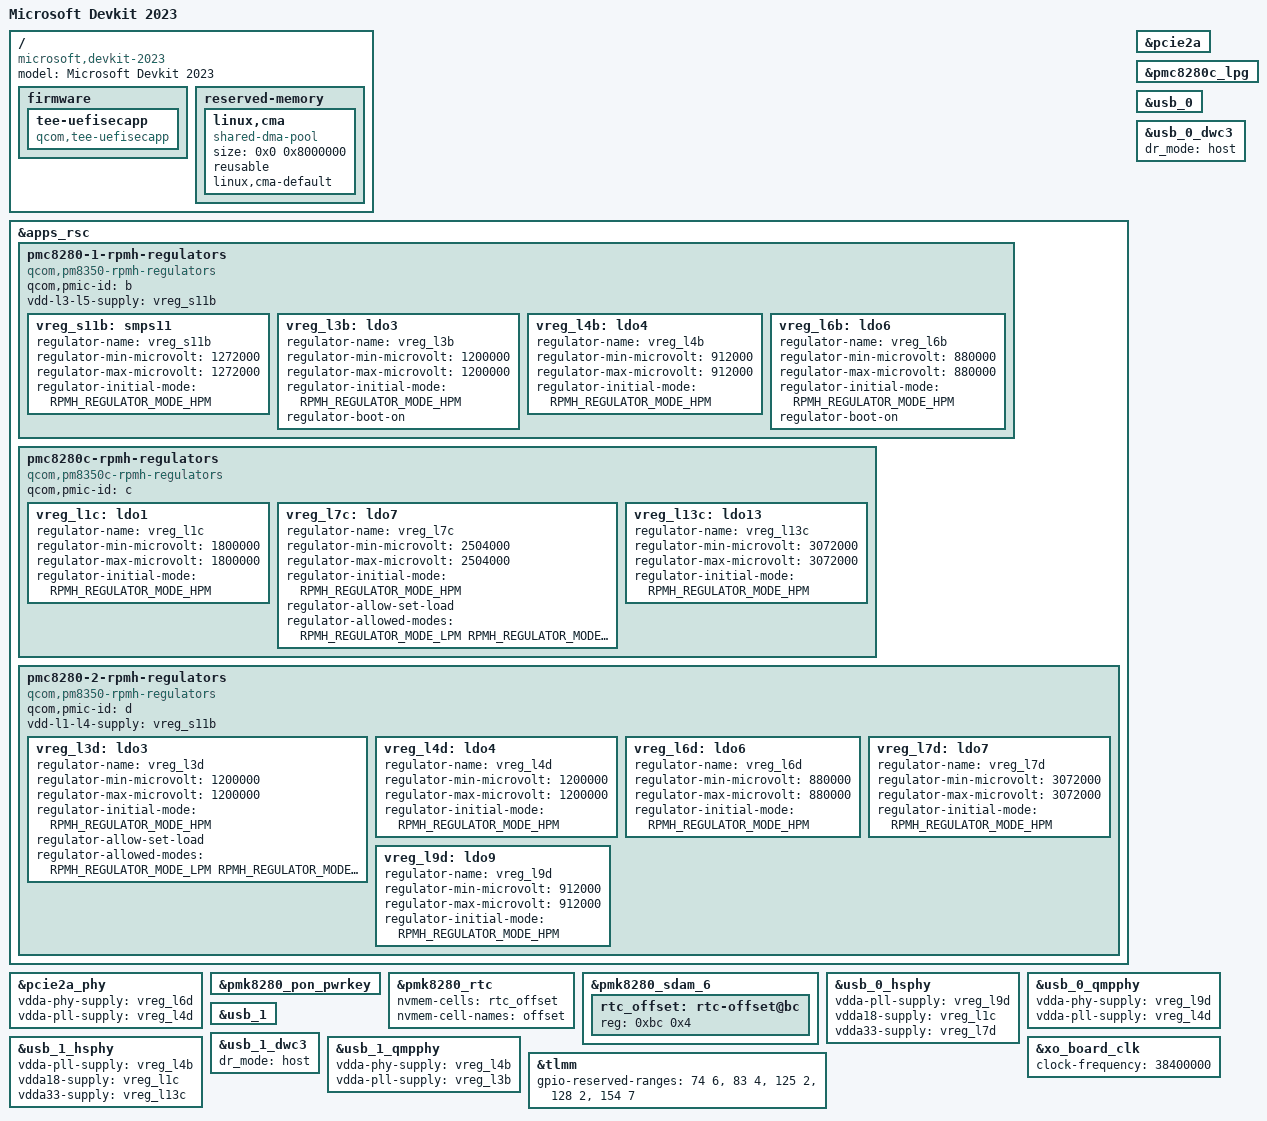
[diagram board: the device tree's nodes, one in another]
// SPDX-License-Identifier: BSD-3-Clause
/*
 * Copyright (c) 2021, The Linux Foundation. All rights reserved.
 * Copyright (c) 2023, Linaro Limited
 */

/dts-v1/;

#include <dt-bindings/gpio/gpio.h>
#include <dt-bindings/regulator/qcom,rpmh-regulator.h>

#include "sc8280xp.dtsi"
#include "sc8280xp-pmics.dtsi"

/ {
	model = "Microsoft Devkit 2023";
	compatible = "microsoft,devkit-2023", "qcom,sc8280xp";

	firmware {
		tee-uefisecapp {
			compatible = "qcom,tee-uefisecapp";
		};
	};

	reserved-memory {
		linux,cma {
			compatible = "shared-dma-pool";
			size = <0x0 0x8000000>;
			reusable;
			linux,cma-default;
		};
	};
};

&apps_rsc {
	pmc8280-1-rpmh-regulators {
		compatible = "qcom,pm8350-rpmh-regulators";
		qcom,pmic-id = "b";

		vdd-l3-l5-supply = <&vreg_s11b>;

		vreg_s11b: smps11 {
			regulator-name = "vreg_s11b";
			regulator-min-microvolt = <1272000>;
			regulator-max-microvolt = <1272000>;
			regulator-initial-mode = <RPMH_REGULATOR_MODE_HPM>;
		};

		vreg_l3b: ldo3 {
			regulator-name = "vreg_l3b";
			regulator-min-microvolt = <1200000>;
			regulator-max-microvolt = <1200000>;
			regulator-initial-mode = <RPMH_REGULATOR_MODE_HPM>;
			regulator-boot-on;
		};

		vreg_l4b: ldo4 {
			regulator-name = "vreg_l4b";
			regulator-min-microvolt = <912000>;
			regulator-max-microvolt = <912000>;
			regulator-initial-mode = <RPMH_REGULATOR_MODE_HPM>;
		};

		vreg_l6b: ldo6 {
			regulator-name = "vreg_l6b";
			regulator-min-microvolt = <880000>;
			regulator-max-microvolt = <880000>;
			regulator-initial-mode = <RPMH_REGULATOR_MODE_HPM>;
			regulator-boot-on;
		};
	};

	pmc8280c-rpmh-regulators {
		compatible = "qcom,pm8350c-rpmh-regulators";
		qcom,pmic-id = "c";

		vreg_l1c: ldo1 {
			regulator-name = "vreg_l1c";
			regulator-min-microvolt = <1800000>;
			regulator-max-microvolt = <1800000>;
			regulator-initial-mode = <RPMH_REGULATOR_MODE_HPM>;
		};

		vreg_l7c: ldo7 {
			regulator-name = "vreg_l7c";
			regulator-min-microvolt = <2504000>;
			regulator-max-microvolt = <2504000>;
			regulator-initial-mode = <RPMH_REGULATOR_MODE_HPM>;
			regulator-allow-set-load;
			regulator-allowed-modes = <RPMH_REGULATOR_MODE_LPM
						   RPMH_REGULATOR_MODE_HPM>;
		};

		vreg_l13c: ldo13 {
			regulator-name = "vreg_l13c";
			regulator-min-microvolt = <3072000>;
			regulator-max-microvolt = <3072000>;
			regulator-initial-mode = <RPMH_REGULATOR_MODE_HPM>;
		};
	};

	pmc8280-2-rpmh-regulators {
		compatible = "qcom,pm8350-rpmh-regulators";
		qcom,pmic-id = "d";

		vdd-l1-l4-supply = <&vreg_s11b>;

		vreg_l3d: ldo3 {
			regulator-name = "vreg_l3d";
			regulator-min-microvolt = <1200000>;
			regulator-max-microvolt = <1200000>;
			regulator-initial-mode = <RPMH_REGULATOR_MODE_HPM>;
			regulator-allow-set-load;
			regulator-allowed-modes = <RPMH_REGULATOR_MODE_LPM
						   RPMH_REGULATOR_MODE_HPM>;
		};

		vreg_l4d: ldo4 {
			regulator-name = "vreg_l4d";
			regulator-min-microvolt = <1200000>;
			regulator-max-microvolt = <1200000>;
			regulator-initial-mode = <RPMH_REGULATOR_MODE_HPM>;
		};

		vreg_l6d: ldo6 {
			regulator-name = "vreg_l6d";
			regulator-min-microvolt = <880000>;
			regulator-max-microvolt = <880000>;
			regulator-initial-mode = <RPMH_REGULATOR_MODE_HPM>;
		};

		vreg_l7d: ldo7 {
			regulator-name = "vreg_l7d";
			regulator-min-microvolt = <3072000>;
			regulator-max-microvolt = <3072000>;
			regulator-initial-mode = <RPMH_REGULATOR_MODE_HPM>;
		};

		vreg_l9d: ldo9 {
			regulator-name = "vreg_l9d";
			regulator-min-microvolt = <912000>;
			regulator-max-microvolt = <912000>;
			regulator-initial-mode = <RPMH_REGULATOR_MODE_HPM>;
		};
	};
};

&pcie2a {
	status = "okay";
};

&pcie2a_phy {
	vdda-phy-supply = <&vreg_l6d>;
	vdda-pll-supply = <&vreg_l4d>;

	status = "okay";
};

&pmc8280c_lpg {
	status = "okay";
};

&pmk8280_pon_pwrkey {
	status = "okay";
};

&pmk8280_rtc {
	nvmem-cells = <&rtc_offset>;
	nvmem-cell-names = "offset";

	status = "okay";
};

&pmk8280_sdam_6 {
	status = "okay";

	rtc_offset: rtc-offset@bc {
		reg = <0xbc 0x4>;
	};
};

&usb_0 {
	status = "okay";
};

&usb_0_dwc3 {
	/* TODO: Define USB-C connector properly */
	dr_mode = "host";
};

&usb_0_hsphy {
	vdda-pll-supply = <&vreg_l9d>;
	vdda18-supply = <&vreg_l1c>;
	vdda33-supply = <&vreg_l7d>;

	status = "okay";
};

&usb_0_qmpphy {
	vdda-phy-supply = <&vreg_l9d>;
	vdda-pll-supply = <&vreg_l4d>;

	status = "okay";
};

&usb_1 {
	status = "okay";
};

&usb_1_dwc3 {
	/* TODO: Define USB-C connector properly */
	dr_mode = "host";
};

&usb_1_hsphy {
	vdda-pll-supply = <&vreg_l4b>;
	vdda18-supply = <&vreg_l1c>;
	vdda33-supply = <&vreg_l13c>;

	status = "okay";
};

&usb_1_qmpphy {
	vdda-phy-supply = <&vreg_l4b>;
	vdda-pll-supply = <&vreg_l3b>;

	status = "okay";
};

&xo_board_clk {
	clock-frequency = <38400000>;
};

/* PINCTRL - additions to nodes defined in sc8280xp.dtsi */

&tlmm {
	gpio-reserved-ranges = <74 6>, <83 4>, <125 2>, <128 2>, <154 7>;
};
